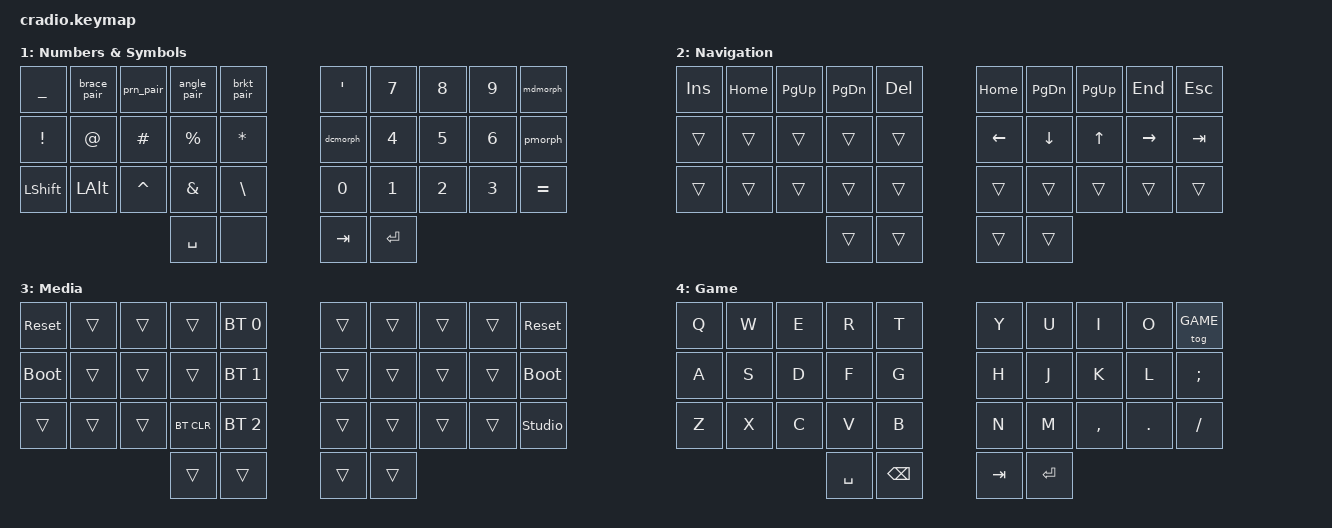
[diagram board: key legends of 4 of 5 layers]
// Copyright ...
// SPDX-License-Identifier: MIT

#include <behaviors.dtsi>
#include <dt-bindings/zmk/keys.h>
#include <dt-bindings/zmk/bt.h>

#define HRML(k1,k2,k3,k4) &ht LGUI k1  &ht LALT k2  &ht LCTRL k3  &ht LSHFT k4
#define HRMR(k1,k2,k3,k4) &ht RSHFT k1  &ht RCTRL k2  &ht RALT k3  &ht RGUI k4

#define BASE 0
#define NUMSYM 1
#define NAV 2
#define MEDIA 3
#define GAME 4

/ {
  behaviors {
    // Home-row mod tap tuning — adjust to taste
    ht: hold_tap {
      compatible = "zmk,behavior-hold-tap";
      #binding-cells = <2>;
      flavor = "tap-preferred";
      tapping-term-ms = <200>;
      quick-tap-ms = <0>;
      bindings = <&kp>, <&kp>; // P1 = held, P2 = tap
    };

    ht_tog: hold_tap_toggle_layer {
      compatible = "zmk,behavior-hold-tap";
      #binding-cells = <2>;
      flavor = "tap-preferred";
      tapping-term-ms = <200>;
      quick-tap-ms = <0>;
      bindings = <&tog>, <&kp>; // P1 = held, P2 = tap
    };

    // PLUS normally, MINUS on modifier 
    pmorph: plus_minus {
        compatible = "zmk,behavior-mod-morph";
        #binding-cells = <0>;
        bindings = <&kp PLUS>, <&kp MINUS>;
        // Treat Shift as the modifier
        mods = <(MOD_LALT|MOD_RALT)>;
    };

    // MULTIPLY normally, DIVIDE on modifier 
    mdmorph: mul_divide {
        compatible = "zmk,behavior-mod-morph";
        #binding-cells = <0>;
        bindings = <&kp ASTRK>, <&kp FSLH>; 
        mods = <(MOD_LALT|MOD_RALT)>;
    };

    // DOT normally, COMMA on modifier
    dcmorph: dot_comma {
        compatible = "zmk,behavior-mod-morph";
        #binding-cells = <0>;
        bindings = <&kp DOT>, <&kp COMMA>;
        mods = <(MOD_LALT|MOD_RALT)>;
    };

    // ── Symmetric pairs: Shift held → send the "right/closing" mate ──
    brkt_pair: bracket_pair {
        compatible = "zmk,behavior-mod-morph";
        #binding-cells = <0>;
        bindings = <&kp LBKT>, <&kp RBKT>;     
        mods = <(MOD_LALT|MOD_RALT)>;
    };

    brace_pair: brace_pair {
        compatible = "zmk,behavior-mod-morph";
        #binding-cells = <0>;
        bindings = <&kp LBRC>, <&kp RBRC>;     
        mods = <(MOD_LALT|MOD_RALT)>;
    };

    prn_pair: prn_pair {
        compatible = "zmk,behavior-mod-morph";
        #binding-cells = <0>;
        bindings = <&kp LPAR>, <&kp RPAR>;     
        mods = <(MOD_LALT|MOD_RALT)>;
    };

    angle_pair: angle_pair {
        compatible = "zmk,behavior-mod-morph";
        #binding-cells = <0>;
        bindings = <&kp LT>, <&kp GT>;
        mods = <(MOD_LALT|MOD_RALT)>;
    };

  };

    keymap {
        compatible = "zmk,keymap";
        BASE {
            display-name = "Base";
            bindings = <
        //╭──────────┬──────────┬──────────┬──────────┬──────────╮        ╭──────────┬──────────┬──────────┬──────────┬──────────╮
        //│  Q       │  W       │  E       │  R       │  T       │        │  Y       │  U       │  I       │  O       │  P       │
            &kp Q      &kp W      &kp E      &kp R      &kp T               &kp Y      &kp U      &kp I      &kp O      &kp P
        //├──────────┼──────────┼──────────┼──────────┼──────────┤        ├──────────┼──────────┼──────────┼──────────┼──────────┤
        //│  A       │  S       │  D       │  F       │  G       │        │  H       │  J       │  K       │  L       │ ; :      │
            HRML(A,        S,         D,         F)     &kp G               &kp H      HRMR(J,     K,         L,        SEMI)
        //├──────────┼──────────┼──────────┼──────────┼──────────┤        ├──────────┼──────────┼──────────┼──────────┼──────────┤
        //│  Z       │  X       │  C       │  V       │  B       │        │  N       │  M       │ , <      │ . >      │ / ?      │
            &kp Z      &kp X      &kp C      &kp V      &kp B               &kp N      &kp M      &kp COMMA  &kp DOT    &kp FSLH
        //╰──────────┴──────────┴──────────┼──────────┼──────────┤        ├──────────┼──────────┼──────────┴──────────┴──────────╯
                                            &lt NAV SPACE &lt NUMSYM BSPC  &lt MEDIA TAB &ht_tog GAME ENTER
        //                                 ╰──────────┴──────────╯        ╰──────────┴──────────╯
            >;
        };

        NUMSYM {
            display-name = "Numbers & Symbols";
            bindings = <
        //╭──────────┬──────────┬──────────┬──────────┬──────────╮   ╭──────────┬──────────┬──────────┬──────────┬──────────╮
        //│ _        │ {}       │  ()      │  <>      │  []      │   │ '"       │ 7        │ 8        │ 9        │  */      │
            &kp UNDER  &brace_pair &prn_pair &angle_pair &brkt_pair    &kp SQT    &kp N7     &kp N8     &kp N9     &mdmorph
        //├──────────┼──────────┼──────────┼──────────┼──────────┤   ├──────────┼──────────┼──────────┼──────────┼──────────┤
        //│ !        │ @        │  #       │ %        │ *        │   │ .,       │ 4        │ 5        │ 6        │  +-      │
            &kp EXCL   &kp AT     &kp HASH   &kp PRCNT  &kp ASTRK      &dcmorph   &kp N4     &kp N5     &kp N6     &pmorph
        //├──────────┼──────────┼──────────┼──────────┼──────────┤   ├──────────┼──────────┼──────────┼──────────┼──────────┤
        //│ Shift    │  ALT     │ ^        │ &        │ \|       │   │ 0        │ 1        │ 2        │ 3        │          │
            &kp LSHIFT  &kp LALT  &kp CARET  &kp AMPS   &kp BSLH      &kp N0     &kp N1     &kp N2     &kp N3     &kp EQUAL
        //╰──────────┴──────────┴──────────┼──────────┼──────────┤   ├──────────┼──────────┼──────────┴──────────┴──────────╯
                                             &kp SPACE   &none       &kp TAB    &kp ENTER
        //                                 ╰──────────┴──────────╯   ╰──────────┴──────────╯
            >;
        };

        NAV {
            display-name = "Navigation";
            bindings = <
        //╭──────────┬──────────┬──────────┬──────────┬──────────╮   ╭──────────┬──────────┬──────────┬──────────┬──────────╮
        //│          │  [       │  {       │  }       │          │   │  ^       │  (       │  )       │  ]       │  ~       │
            &kp INS     &kp HOME   &kp PG_UP   &kp PG_DN   &kp DEL     &kp HOME   &kp PG_DN   &kp PG_UP   &kp END    &kp ESC
        //├──────────┼──────────┼──────────┼──────────┼──────────┤   ├──────────┼──────────┼──────────┼──────────┼──────────┤
        //│          │          │          │          │          │   │  *       │  -       │  =       │  \       │  `       │
            &trans     &trans     &trans     &trans     &trans         &kp LEFT   &kp DOWN   &kp UP    &kp RIGHT   &kp TAB
        //├──────────┼──────────┼──────────┼──────────┼──────────┤   ├──────────┼──────────┼──────────┼──────────┼──────────┤
        //│          │          │          │          │          │   │  &       │  _       │  +       │  │       │          │
            &trans     &trans     &trans     &trans     &trans         &trans     &trans     &trans     &trans     &trans
        //╰──────────┴──────────┴──────────┼──────────┼──────────┤   ├──────────┼──────────┼──────────┴──────────┴──────────╯
                                             &trans     &trans         &trans     &trans
        //                                 ╰──────────┴──────────╯   ╰──────────┴──────────╯
            >;
        };

        MEDIA {
            display-name = "Media";
            bindings = <
        //╭──────────┬──────────┬──────────┬──────────┬──────────╮   ╭──────────┬──────────┬──────────┬──────────┬──────────╮
        //│ RESET    │          │          │          │PROFILE 0 │   │          │          │          │          │  RESET   │
           &sys_reset  &trans     &trans     &trans    &bt BT_SEL 0    &trans     &trans     &trans     &trans    &sys_reset
        //├──────────┼──────────┼──────────┼──────────┼──────────┤   ├──────────┼──────────┼──────────┼──────────┼──────────┤
        //│BOOTLOADER│          │          │          │PROFILE 1 │   │          │          │          │          │BOOTLOADER│
          &bootloader  &trans     &trans     &trans    &bt BT_SEL 1    &trans     &trans     &trans     &trans    &bootloader
        //├──────────┼──────────┼──────────┼──────────┼──────────┤   ├──────────┼──────────┼──────────┼──────────┼──────────┤
        //│          │          │          │ CLEAR BT │PROFILE 2 │   │          │          │          │          │          │
            &trans     &trans     &trans    &bt BT_CLR &bt BT_SEL 2    &trans     &trans     &trans     &trans     &studio_unlock
        //╰──────────┴──────────┴──────────┼──────────┼──────────┤   ├──────────┼──────────┼──────────┴──────────┴──────────╯
                                             &trans     &trans         &trans     &trans
        //                                 ╰──────────┴──────────╯   ╰──────────┴──────────╯
            >;
        };

        GAME {
            display-name = "Game";
            bindings = <
        //╭──────────┬──────────┬──────────┬──────────┬──────────╮   ╭──────────┬──────────┬──────────┬──────────┬──────────╮
        //│  Q       │  W       │  E       │  R       │  T       │   │  Y       │  U       │  I       │  O       │  P       │
            &kp Q      &kp W      &kp E      &kp R      &kp T          &kp Y      &kp U      &kp I      &kp O      &tog GAME
        //├──────────┼──────────┼──────────┼──────────┼──────────┤   ├──────────┼──────────┼──────────┼──────────┼──────────┤
        //│  A       │  S       │  D       │  F       │  G       │   │  H       │  J       │  K       │  L       │ ; :      │
             &kp A      &kp S      &kp D      &kp F      &kp G          &kp H      &kp J      &kp K      &kp L     &kp SEMI
        //├──────────┼──────────┼──────────┼──────────┼──────────┤   ├──────────┼──────────┼──────────┼──────────┼──────────┤
        //│  Z       │  X       │  C       │  V       │  B       │   │  N       │  M       │ , <      │ . >      │ / ?      │
            &kp Z      &kp X      &kp C      &kp V      &kp B          &kp N      &kp M      &kp COMMA  &kp DOT    &kp FSLH
        //╰──────────┴──────────┴──────────┼──────────┼──────────┤   ├──────────┼──────────┼──────────┴──────────┴──────────╯
                                             &kp SPACE  &kp BSPC       &kp TAB  &kp ENTER
        //                                 ╰──────────┴──────────╯   ╰──────────┴──────────╯
            >;
        };

    };
};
